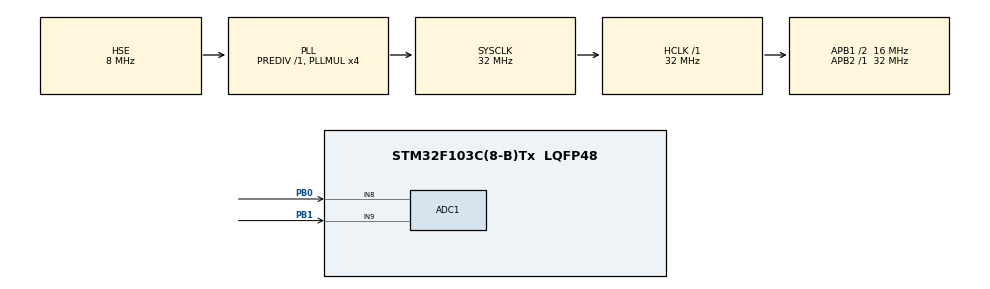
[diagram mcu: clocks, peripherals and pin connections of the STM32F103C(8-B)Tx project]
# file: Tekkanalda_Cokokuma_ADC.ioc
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ADC1.Channel-0\#ChannelRegularConversion=ADC_CHANNEL_8
ADC1.Channel-1\#ChannelRegularConversion=ADC_CHANNEL_9
ADC1.ContinuousConvMode=ENABLE
ADC1.NbrOfConversion=2
ADC1.NbrOfConversionFlag=1
ADC1.Rank-0\#ChannelRegularConversion=1
ADC1.Rank-1\#ChannelRegularConversion=2
ADC1.SamplingTime-0\#ChannelRegularConversion=ADC_SAMPLETIME_71CYCLES_5
ADC1.SamplingTime-1\#ChannelRegularConversion=ADC_SAMPLETIME_71CYCLES_5
ADC1.master=1
Dma.ADC1.0.Direction=DMA_PERIPH_TO_MEMORY
Dma.ADC1.0.Instance=DMA1_Channel1
Dma.ADC1.0.MemDataAlignment=DMA_MDATAALIGN_WORD
Dma.ADC1.0.MemInc=DMA_MINC_ENABLE
Dma.ADC1.0.Mode=DMA_CIRCULAR
Dma.ADC1.0.PeriphDataAlignment=DMA_PDATAALIGN_WORD
Dma.ADC1.0.PeriphInc=DMA_PINC_DISABLE
Dma.ADC1.0.Priority=DMA_PRIORITY_LOW
Dma.Request0=ADC1
Mcu.Family=STM32F1
Mcu.Name=STM32F103C(8-B)Tx
Mcu.Package=LQFP48
NVIC.DMA1_Channel1_IRQn=true\:0\:0\:false\:false\:true\:false\:true
NVIC.PriorityGroup=NVIC_PRIORITYGROUP_4
PA13.Mode=Serial_Wire
PA13.Signal=SYS_JTMS-SWDIO
PA14.Mode=Serial_Wire
PA14.Signal=SYS_JTCK-SWCLK
PB0.Signal=ADCx_IN8
PB1.Signal=ADCx_IN9
PD0-OSC_IN.Mode=HSE-External-Oscillator
PD0-OSC_IN.Signal=RCC_OSC_IN
PD1-OSC_OUT.Mode=HSE-External-Oscillator
PD1-OSC_OUT.Signal=RCC_OSC_OUT
ProjectManager.HeapSize=0x00
ProjectManager.StackSize=0x400
ProjectManager.TargetToolchain=STM32CubeIDE
RCC.ADCPresc=RCC_ADCPCLK2_DIV4
RCC.AHBFreq_Value=32000000
RCC.APB1CLKDivider=RCC_HCLK_DIV2
RCC.APB1Freq_Value=16000000
RCC.APB1TimFreq_Value=32000000
RCC.APB2Freq_Value=32000000
RCC.APB2TimFreq_Value=32000000
RCC.HCLKFreq_Value=32000000
RCC.PLLMUL=RCC_PLL_MUL4
RCC.PLLSourceVirtual=RCC_PLLSOURCE_HSE
RCC.SYSCLKFreq_VALUE=32000000
RCC.SYSCLKSource=RCC_SYSCLKSOURCE_PLLCLK
RCC.USBFreq_Value=32000000
SH.ADCx_IN8.0=ADC1_IN8,IN8
SH.ADCx_IN9.0=ADC1_IN9,IN9
board=custom

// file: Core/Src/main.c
/* USER CODE BEGIN Header */
/**
  ******************************************************************************
  * @file           : main.c
  * @brief          : Main program body
  ******************************************************************************
  * @attention
  *
  * <h2><center>&copy; Copyright (c) 2022 STMicroelectronics.
  * All rights reserved.</center></h2>
  *
  * This software component is licensed by ST under BSD 3-Clause license,
  * the "License"; You may not use this file except in compliance with the
  * License. You may obtain a copy of the License at:
  *                        opensource.org/licenses/BSD-3-Clause
  *
  ******************************************************************************
  */
/* USER CODE END Header */
#include "main.h"

/* USER CODE BEGIN PD */
uint32_t data[2];
uint32_t adcbuffer[2];
/* USER CODE END PD */

ADC_HandleTypeDef hadc1;
DMA_HandleTypeDef hdma_adc1;

void SystemClock_Config(void);
static void MX_GPIO_Init(void);
static void MX_DMA_Init(void);
static void MX_ADC1_Init(void);
/* USER CODE BEGIN PFP */
void HAL_ADC_ConvCpltCallback(ADC_HandleTypeDef* hadc)
{

  if(hadc->Instance == ADC1)
  {
	data[0]= adcbuffer[0];
	data[1]= adcbuffer[1];

  }
}
/* USER CODE END PFP */

int main(void)
{

  /* MCU Configuration--------------------------------------------------------*/

  /* Reset of all peripherals, Initializes the Flash interface and the Systick. */
  HAL_Init();

  /* Configure the system clock */
  SystemClock_Config();

  /* Initialize all configured peripherals */
  MX_GPIO_Init();
  MX_DMA_Init();
  MX_ADC1_Init();
  /* USER CODE BEGIN 2 */
  HAL_ADC_Start_DMA(&hadc1, adcbuffer, 2);
  /* USER CODE END 2 */

  /* Infinite loop */
  while (1)
  {

  }
}

void SystemClock_Config(void)
{
  RCC_OscInitTypeDef RCC_OscInitStruct = {0};
  RCC_ClkInitTypeDef RCC_ClkInitStruct = {0};
  RCC_PeriphCLKInitTypeDef PeriphClkInit = {0};

  /** Initializes the RCC Oscillators according to the specified parameters
  * in the RCC_OscInitTypeDef structure.
  */
  RCC_OscInitStruct.OscillatorType = RCC_OSCILLATORTYPE_HSE;
  RCC_OscInitStruct.HSEState = RCC_HSE_ON;
  RCC_OscInitStruct.HSEPredivValue = RCC_HSE_PREDIV_DIV1;
  RCC_OscInitStruct.HSIState = RCC_HSI_ON;
  RCC_OscInitStruct.PLL.PLLState = RCC_PLL_ON;
  RCC_OscInitStruct.PLL.PLLSource = RCC_PLLSOURCE_HSE;
  RCC_OscInitStruct.PLL.PLLMUL = RCC_PLL_MUL4;
  if (HAL_RCC_OscConfig(&RCC_OscInitStruct) != HAL_OK)
  {
    Error_Handler();
  }
  /** Initializes the CPU, AHB and APB buses clocks
  */
  RCC_ClkInitStruct.ClockType = RCC_CLOCKTYPE_HCLK|RCC_CLOCKTYPE_SYSCLK
                              |RCC_CLOCKTYPE_PCLK1|RCC_CLOCKTYPE_PCLK2;
  RCC_ClkInitStruct.SYSCLKSource = RCC_SYSCLKSOURCE_PLLCLK;
  RCC_ClkInitStruct.AHBCLKDivider = RCC_SYSCLK_DIV1;
  RCC_ClkInitStruct.APB1CLKDivider = RCC_HCLK_DIV2;
  RCC_ClkInitStruct.APB2CLKDivider = RCC_HCLK_DIV1;

  if (HAL_RCC_ClockConfig(&RCC_ClkInitStruct, FLASH_LATENCY_1) != HAL_OK)
  {
    Error_Handler();
  }
  PeriphClkInit.PeriphClockSelection = RCC_PERIPHCLK_ADC;
  PeriphClkInit.AdcClockSelection = RCC_ADCPCLK2_DIV4;
  if (HAL_RCCEx_PeriphCLKConfig(&PeriphClkInit) != HAL_OK)
  {
    Error_Handler();
  }
}

static void MX_ADC1_Init(void)
{

  ADC_ChannelConfTypeDef sConfig = {0};

  /** Common config
  */
  hadc1.Instance = ADC1;
  hadc1.Init.ScanConvMode = ADC_SCAN_ENABLE;
  hadc1.Init.ContinuousConvMode = ENABLE;
  hadc1.Init.DiscontinuousConvMode = DISABLE;
  hadc1.Init.ExternalTrigConv = ADC_SOFTWARE_START;
  hadc1.Init.DataAlign = ADC_DATAALIGN_RIGHT;
  hadc1.Init.NbrOfConversion = 2;
  if (HAL_ADC_Init(&hadc1) != HAL_OK)
  {
    Error_Handler();
  }
  /** Configure Regular Channel
  */
  sConfig.Channel = ADC_CHANNEL_8;
  sConfig.Rank = ADC_REGULAR_RANK_1;
  sConfig.SamplingTime = ADC_SAMPLETIME_71CYCLES_5;
  if (HAL_ADC_ConfigChannel(&hadc1, &sConfig) != HAL_OK)
  {
    Error_Handler();
  }
  /** Configure Regular Channel
  */
  sConfig.Channel = ADC_CHANNEL_9;
  sConfig.Rank = ADC_REGULAR_RANK_2;
  if (HAL_ADC_ConfigChannel(&hadc1, &sConfig) != HAL_OK)
  {
    Error_Handler();
  }

}

static void MX_DMA_Init(void)
{

  /* DMA controller clock enable */
  __HAL_RCC_DMA1_CLK_ENABLE();

  /* DMA interrupt init */
  /* DMA1_Channel1_IRQn interrupt configuration */
  HAL_NVIC_SetPriority(DMA1_Channel1_IRQn, 0, 0);
  HAL_NVIC_EnableIRQ(DMA1_Channel1_IRQn);

}

static void MX_GPIO_Init(void)
{

  /* GPIO Ports Clock Enable */
  __HAL_RCC_GPIOD_CLK_ENABLE();
  __HAL_RCC_GPIOB_CLK_ENABLE();
  __HAL_RCC_GPIOA_CLK_ENABLE();

}

void Error_Handler(void)
{
  __disable_irq();
  while (1)
  {
  }
}

/************************ (C) COPYRIGHT STMicroelectronics *****END OF FILE****/
